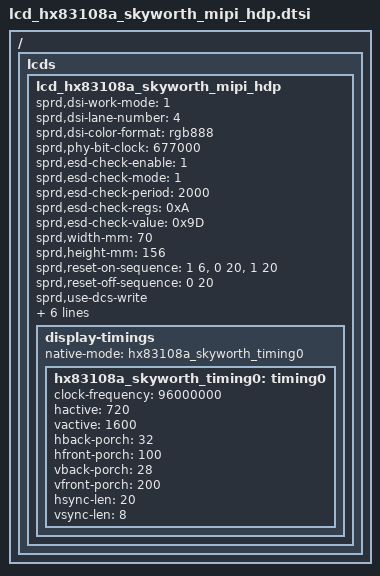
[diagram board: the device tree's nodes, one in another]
/*
 * hx83108a skyworth LCD config dtsi file for spreadtrum
 *
 * Copyright (C) 2018, Spreadtrum Communications Inc.
 *
 * SPDX-License-Identifier: (GPL-2.0+ OR MIT)
 */

/ {
	fragment {
		target-path = "/";
		__overlay__ {
			lcds {
				lcd_hx83108a_skyworth_mipi_hdp: lcd_hx83108a_skyworth_mipi_hdp {

					sprd,dsi-work-mode = <1>; /* video burst mode*/
//					sprd,dsi-work-mode = <3>; /* video SPRD_DSI_MODE_VIDEO_SYNC_EVENT mode*/
					sprd,dsi-lane-number = <4>;
					sprd,dsi-color-format = "rgb888";


					sprd,phy-bit-clock = <677000>;	/* kbps */
//					sprd,phy-escape-clock = <20000>;/* kHz */

					sprd,esd-check-enable = <1>;
					sprd,esd-check-mode = <1>;		//1: te_check
					sprd,esd-check-period = <2000>;
					sprd,esd-check-regs = <0xA>;
					sprd,esd-check-value = <0x9D>;
					
					sprd,width-mm = <70>;
					sprd,height-mm = <156>;
					
					sprd,reset-on-sequence = <1 6>, <0 20>, <1 20>;
					sprd,reset-off-sequence = <0 20>;

					sprd,use-dcs-write;

					sprd,initial-command = [
						  /* Driver_RB9H_BK0 */
						  39 00 00 04 B9 83 10 8A
						  15 00 00 02 BD 00

						  /* Driver_RB1H_BK0 */
						  39 00 00 12 B1 2C 37 37 32 32 22 43 57 16 16 0C 98 21 11 46 34 0F

						  /* Driver_RB2H_BK0 */
						  39 00 00 10 B2 00 26 D0 40 00 1A C6 00 98 11 01 00 00 10 22

						  /* Driver_RB4H_BK0 */
						  39 00 00 0F B4 97 7D 97 7D 97 7D 97 7D 97 7D 02 8D 01 FF

						  /* Driver_RB6H_BK0 */
//						  39 00 00 04 B6 20 20 03

						  /* Driver_RBAH_BK0 */
						  39 00 00 05 BA 73 00 A8 95

						  /* Driver_RBFH_BK0 */
						  39 00 00 03 BF FC 40

						  /* Driver_RC0H_BK0 */
						  39 00 00 07 C0 33 33 11 00 B3 DF

                          39 00 00 2F E0 00 03 09 0F 13 1B 30 35 39 38 53 5B 64 78 7B 87 93 A8 AA 55 5E 6A 73 00 03 09 0F 13 1B 30 35 39 38 53 5B 64 78 7B 87 93 A8 AA 55 5E 6A 73

						  /* Driver_RE9H_BK0 */
						  15 00 00 02 E9 C5

						  /* Driver_RC7H_BK0 */
						  39 00 00 09 C7 88 CA 08 14 02 04 04 04

						  /* Driver_RE9H_BK0 */
						  15 00 00 02 E9 3F

						  /* Driver_RE9H_BK0 */
						  15 00 00 02 E9 C6

						  /* Driver_RC8H_BK0 */
						  39 00 00 04 C8 87 13 01

						  /* Driver_RE9H_BK0 */
						  15 00 00 02 E9 3F

						  /* Driver_RCCH_BK0 */
						  15 00 00 02 CC 02

						  /* Driver_RCBH_BK0 */
						  39 00 00 06 CB 13 08 E0 0E 79

						  /* Driver_RD1H_BK0 */
						  39 00 00 03 D1 27 02

						  /* Driver_RD2H_BK0 */
						  39 00 00 05 D2 00 00 00 00

						  /* Driver_RD3H_BK0 */
						  39 00 00 20 D3 C0 00 10 10 00 00 4F 4F 44 4B 1C 1C 1C 1C 32 10 18 00 18 32 16 5C 06 5C 32 16 62 06 62 00 00

						  /* Driver_RD5H_BK0 */
						  39 00 00 2D D5 18 18 18 18 28 29 24 25 1E 1E 1F 1F 00 01 02 03 04 05 06 07 08 09 0A 0B 0C 0D 0E 0F 20 21 18 18 18 18 18 18 18 18 18 18 18 18 18 18

						  /* Driver_RD6H_BK0 */
						  39 00 00 2D D6 18 18 18 18 29 28 21 20 1E 1E 1F 1F 0F 0E 0D 0C 0B 0A 09 08 07 06 05 04 03 02 01 00 25 24 18 18 18 18 18 18 18 18 18 18 18 18 18 18

						  /* Driver_RD8H_BK0 */
						  39 00 00 25 D8 AA AA AA A8 00 00 AA AA AA A8 00 00 8A EA AA A8 00 00 8A EA AA A8 00 00 00 00 00 00 00 00 00 00 00 00 00 00

						  /* Driver_RE7H_BK0 */
						  39 00 00 14 E7 07 14 14 0D 0F 84 00 3C 3C 32 32 00 00 00 00 79 11 01 02
						  15 00 00 02 BD 01

						  /* Driver_RB1H_BK1 */
						  39 00 00 03 B1 01 1B

						  /* Driver_RBFH_BK1 */
						  15 00 00 02 BF 0E

						  /* Driver_RD2H_BK1 */
						  39 00 00 05 D2 00 00 00 3C

						  /* Driver_RD8H_BK1 */
						  39 00 00 25 D8 FF FF FF FC 00 00 FF FF FF FC 00 00 00 00 00 00 00 00 00 00 00 00 00 00 00 00 00 00 00 00 00 00 00 00 00 00

						  /* Driver_RE7H_BK1 */
						  39 00 00 0E E7 01 00 20 01 00 00 31 02 33 00 1B 00 00
						  15 00 00 02 BD 02

						  /* Driver_RD8H_BK2 */
						  39 00 00 0D D8 FF FF FF FF FF F0 FF FF FF FF FF F0
						  15 00 00 02 BD 03

						  /* Driver_RD8H_BK3 */
						  39 00 00 19 D8 AA FA AA AA AA A0 AA FA AA AA AA A0 AA AA AA AA AA A0 AA AA AA AA AA A0
						  15 00 00 02 BD 00

						  15 00 00 02 35 00

						  /* Driver_R11H_BK0 */
						  15 78 00 02 11 00

						  /* Driver_R29H_BK0 */
						  15 32 00 02 29 00

						  /* Driver_RE9H_BK0 */
						  15 00 00 02 E9 FF

						  /* Driver_RBFH_BK0 */
						  15 00 00 02 BF 02

						  /* Driver_RE9H_BK0 */
						  15 00 00 02 E9 3F

						  /* Driver_RB9H_BK0 */
						  39 00 00 04 B9 00 00 00
						];

					sprd,sleep-in-command = [
						05 0A 00 01 28
						05 78 00 01 10
						39 00 00 04 B9 83 10 8A
						15 00 00 02 BD 00
						15 30 00 02 B1 2D
					];

					sprd,sleep-out-command = [
					  13 78 00 01 11
					  13 64 00 01 29
					];

					display-timings {
						native-mode = <&hx83108a_skyworth_timing0>;

						hx83108a_skyworth_timing0: timing0 {
							clock-frequency = <96000000>;
							hactive = <720>;
							vactive = <1600>;
							hback-porch = <32>;
							hfront-porch = <100>;
							vback-porch = <28>;
							vfront-porch = <200>;
							hsync-len = <20>;
							vsync-len = <8>;
						};
					};
				};
			};
		};
	};
};
